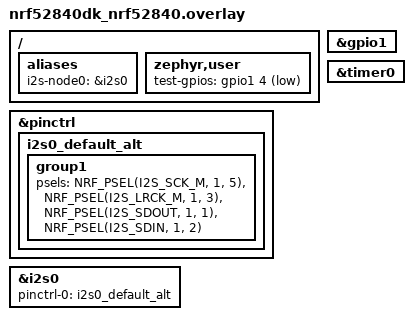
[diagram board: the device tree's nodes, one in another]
/*
 * Copyright (c) 2025 Nordic Semiconductor ASA
 *
 * SPDX-License-Identifier: LicenseRef-Nordic-5-Clause
 */

/* Test requires wire connection:
 *  - I2S_LRCK_M with test-gpios -> P1.03 - P1.04.
 */

/ {
	aliases {
		i2s-node0 = &i2s0;
	};
};

/ {
	zephyr,user {
		test-gpios = <&gpio1 4 GPIO_ACTIVE_LOW>;
	};
};

&pinctrl {
	i2s0_default_alt: i2s0_default_alt {
		group1 {
			psels = <NRF_PSEL(I2S_SCK_M, 1, 5)>,
				<NRF_PSEL(I2S_LRCK_M, 1, 3)>,
				<NRF_PSEL(I2S_SDOUT, 1, 1)>,
				<NRF_PSEL(I2S_SDIN, 1, 2)>;
		};
	};
};

&gpio1 {
	status = "okay";
};

&i2s0 {
	status = "okay";
	pinctrl-0 = <&i2s0_default_alt>;
	pinctrl-names = "default";
};

&timer0 {
	status = "okay";
};
